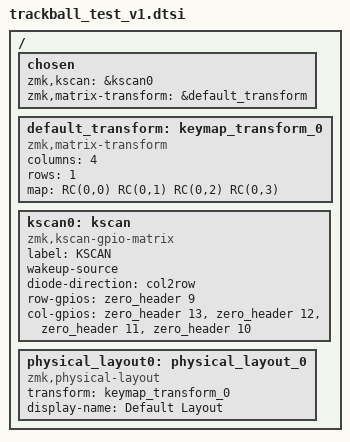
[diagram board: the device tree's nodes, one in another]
#include <dt-bindings/zmk/matrix_transform.h>

/ {
	chosen {
		zmk,kscan = &kscan0;
		zmk,matrix-transform = &default_transform;
		// zephyr,display = &oled;
		// zephyr,console = &cdc_acm_uart;
	};

	default_transform: keymap_transform_0 {
		compatible = "zmk,matrix-transform";
		columns = <4>;
		rows = <1>;
		map = <
		//   Key 1 | Key 2 | Key 3 | Key 4
			RC(0,0) RC(0,1) RC(0,2) RC(0,3)
		>;
	};

	kscan0: kscan {
		compatible = "zmk,kscan-gpio-matrix";
		label = "KSCAN";
		wakeup-source;
		diode-direction = "col2row";
		row-gpios
            = <&zero_header 9 (GPIO_ACTIVE_HIGH | GPIO_PULL_DOWN)>
            ;
		
		col-gpios
            = <&zero_header 13 GPIO_ACTIVE_HIGH>
			, <&zero_header 12 GPIO_ACTIVE_HIGH>
			, <&zero_header 11 GPIO_ACTIVE_HIGH>
			, <&zero_header 10 GPIO_ACTIVE_HIGH>
			;
	};

	physical_layout0: physical_layout_0 {
        compatible = "zmk,physical-layout";
		transform = <&keymap_transform_0>;
        display-name = "Default Layout";
    };

};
